# AT90PWM3B register map
Vendor: Atmel; File version: 1.0
CPU: other r0p0, little endian, no MPU, no FPU, 4 interrupt priority bits
Registers are 8-bit, read-write, reset 0x0 unless marked. A register's access mark holds for its fields unless they carry their own. Offsets are from the block's base; [hi:lo] are bit positions.

## PSC1 — Power Stage Controller
Base 0x000000A2
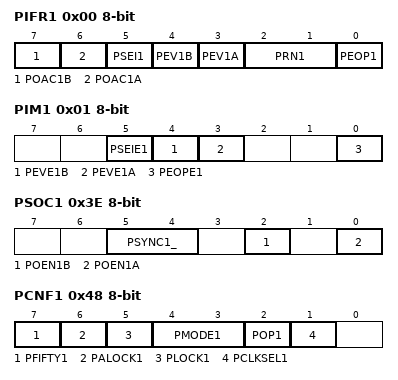
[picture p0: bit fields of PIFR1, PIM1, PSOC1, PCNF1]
0x00 PIFR1 — PSC1 Interrupt Flag Register
  [7] POAC1B — PSC 1 Output B Activity
  [6] POAC1A — PSC 1 Output A Activity
  [5] PSEI1 — PSC 1 Synchro Error Interrupt
  [4] PEV1B — External Event B Interrupt
  [3] PEV1A — External Event A Interrupt
  [2:1] PRN1 — Ramp Number
  [0] PEOP1 — End of PSC1 Interrupt
0x01 PIM1 — PSC1 Interrupt Mask Register
  [5] PSEIE1 — PSC 1 Synchro Error Interrupt Enable
  [4] PEVE1B — External Event B Interrupt Enable
  [3] PEVE1A — External Event A Interrupt Enable
  [0] PEOPE1 — End of Cycle Interrupt Enable
0x3E PSOC1 — PSC1 Synchro and Output Configuration
  [5:4] PSYNC1_ — Synchronization Out for ADC Selection
  [2] POEN1B — PSCOUT11 Output Enable
  [0] POEN1A — PSCOUT10 Output Enable
0x40 OCR1SA 16-bit (reset mask 0xFF) — Output Compare SA Register
  [11:0] OCR1SA — Output Compare 1 SA
0x42 OCR1RA 16-bit (reset mask 0xFF) — Output Compare RA Register
  [11:0] OCR1RA — Output Compare 1 RA
0x44 OCR1SB 16-bit (reset mask 0xFF) — Output Compare SB Register
  [11:0] OCR1SB — Output Compare 1 SB
0x46 OCR1RB 16-bit (reset mask 0xFF) — Output Compare RB Register
  [15:0] OCR1RB — Output Compare 1 RB
0x48 PCNF1 — PSC 1 Configuration Register
  [7] PFIFTY1 — PSC 1 Fifty
  [6] PALOCK1 — PSC 1 Autolock
  [5] PLOCK1 — PSC 1 Lock
  [4:3] PMODE1 — PSC 1 Mode
  [2] POP1 — PSC 1 Output Polarity
  [1] PCLKSEL1 — PSC 1 Input Clock Select
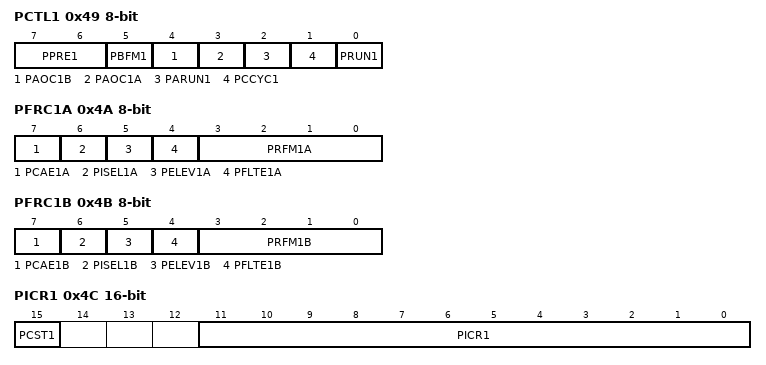
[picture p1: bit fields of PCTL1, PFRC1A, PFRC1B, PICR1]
0x49 PCTL1 — PSC 1 Control Register
  [7:6] PPRE1 — PSC 1 Prescaler Selects
  [5] PBFM1 — Balance Flank Width Modulation
  [4] PAOC1B — PSC 1 Asynchronous Output Control B
  [3] PAOC1A — PSC 1 Asynchronous Output Control A
  [2] PARUN1 — PSC1 Auto Run
  [1] PCCYC1 — PSC1 Complete Cycle
  [0] PRUN1 — PSC 1 Run
0x4A PFRC1A — PSC 1 Input B Control
  [7] PCAE1A — PSC 1 Capture Enable Input Part A
  [6] PISEL1A — PSC 1 Input Select for Part A
  [5] PELEV1A — PSC 1 Edge Level Selector on Input Part A
  [4] PFLTE1A — PSC 1 Filter Enable on Input Part A
  [3:0] PRFM1A — PSC 1 Retrigger and Fault Mode for Part A
0x4B PFRC1B — PSC 1 Input B Control
  [7] PCAE1B — PSC 1 Capture Enable Input Part B
  [6] PISEL1B — PSC 1 Input Select for Part B
  [5] PELEV1B — PSC 1 Edge Level Selector on Input Part B
  [4] PFLTE1B — PSC 1 Filter Enable on Input Part B
  [3:0] PRFM1B — PSC 1 Retrigger and Fault Mode for Part B
0x4C PICR1 16-bit (reset mask 0xFF) — PSC 1 Input Capture Register
  [15] PCST1 — PSC 1 Input Capture Software Trig
  [11:0] PICR1 — PSC 1 Input Capture Bytes

## PSC2 — Power Stage Controller
Base 0x000000A4
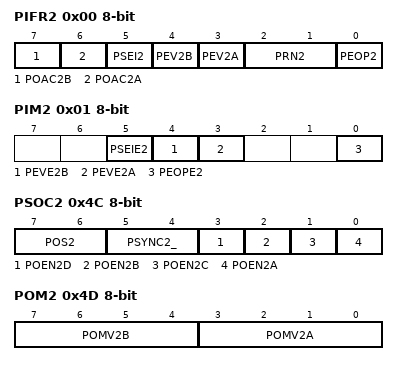
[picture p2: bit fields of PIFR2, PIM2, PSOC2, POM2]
0x00 PIFR2 — PSC2 Interrupt Flag Register
  [7] POAC2B — PSC 2 Output A Activity
  [6] POAC2A — PSC 2 Output A Activity
  [5] PSEI2 — PSC 2 Synchro Error Interrupt
  [4] PEV2B — External Event B Interrupt
  [3] PEV2A — External Event A Interrupt
  [2:1] PRN2 — Ramp Number
  [0] PEOP2 — End of PSC2 Interrupt
0x01 PIM2 — PSC2 Interrupt Mask Register
  [5] PSEIE2 — PSC 2 Synchro Error Interrupt Enable
  [4] PEVE2B — External Event B Interrupt Enable
  [3] PEVE2A — External Event A Interrupt Enable
  [0] PEOPE2 — End of Cycle Interrupt Enable
0x4C PSOC2 — PSC2 Synchro and Output Configuration
  [7:6] POS2 — PSC 2 Output 23 Select
  [5:4] PSYNC2_ — Synchronization Out for ADC Selection
  [3] POEN2D — PSCOUT23 Output Enable
  [2] POEN2B — PSCOUT21 Output Enable
  [1] POEN2C — PSCOUT22 Output Enable
  [0] POEN2A — PSCOUT20 Output Enable
0x4D POM2 — PSC 2 Output Matrix
  [7:4] POMV2B — Output Matrix Output B Ramps
  [3:0] POMV2A — Output Matrix Output A Ramps
0x4E OCR2SA 16-bit (reset mask 0xFF) — Output Compare 2 SA Register
  [11:0] OCR2SA — Output Compare SA
0x50 OCR2RA 16-bit (reset mask 0xFF) — Output Compare 2 RA Register
  [11:0] OCR2RA — Output Compare RA
0x52 OCR2SB 16-bit (reset mask 0xFF) — Output Compare 2 SB Register
  [11:0] OCR2SB — Output Compare SB
0x54 OCR2RB 16-bit (reset mask 0xFF) — Output Compare 2 RB Register
  [15:0] OCR2RB — Output Compare RB
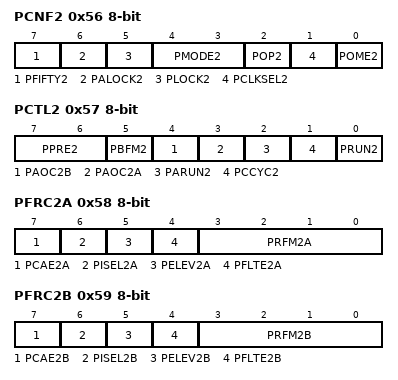
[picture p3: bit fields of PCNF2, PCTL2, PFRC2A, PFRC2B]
0x56 PCNF2 — PSC 2 Configuration Register
  [7] PFIFTY2 — PSC 2 Fifty
  [6] PALOCK2 — PSC 2 Autolock
  [5] PLOCK2 — PSC 2 Lock
  [4:3] PMODE2 — PSC 2 Mode
  [2] POP2 — PSC 2 Output Polarity
  [1] PCLKSEL2 — PSC 2 Input Clock Select
  [0] POME2 — PSC 2 Output Matrix Enable
0x57 PCTL2 — PSC 2 Control Register
  [7:6] PPRE2 — PSC 2 Prescaler Selects
  [5] PBFM2 — Balance Flank Width Modulation
  [4] PAOC2B — PSC 2 Asynchronous Output Control B
  [3] PAOC2A — PSC 2 Asynchronous Output Control A
  [2] PARUN2 — PSC2 Auto Run
  [1] PCCYC2 — PSC2 Complete Cycle
  [0] PRUN2 — PSC 2 Run
0x58 PFRC2A — PSC 2 Input B Control
  [7] PCAE2A — PSC 2 Capture Enable Input Part A
  [6] PISEL2A — PSC 2 Input Select for Part A
  [5] PELEV2A — PSC 2 Edge Level Selector on Input Part A
  [4] PFLTE2A — PSC 2 Filter Enable on Input Part A
  [3:0] PRFM2A — PSC 2 Retrigger and Fault Mode for Part A
0x59 PFRC2B — PSC 2 Input B Control
  [7] PCAE2B — PSC 2 Capture Enable Input Part B
  [6] PISEL2B — PSC 2 Input Select for Part B
  [5] PELEV2B — PSC 2 Edge Level Selector on Input Part B
  [4] PFLTE2B — PSC 2 Filter Enable on Input Part B
  [3:0] PRFM2B — PSC 2 Retrigger and Fault Mode for Part B
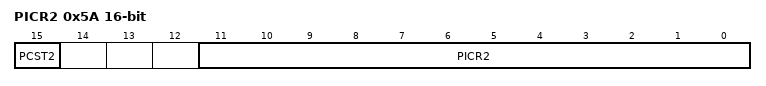
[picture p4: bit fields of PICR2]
0x5A PICR2 16-bit (reset mask 0xFF) — PSC 2 Input Capture Register
  [15] PCST2 — PSC 2 Input Capture Software Trig
  [11:0] PICR2 — PSC 2 Input Capture Bytes
